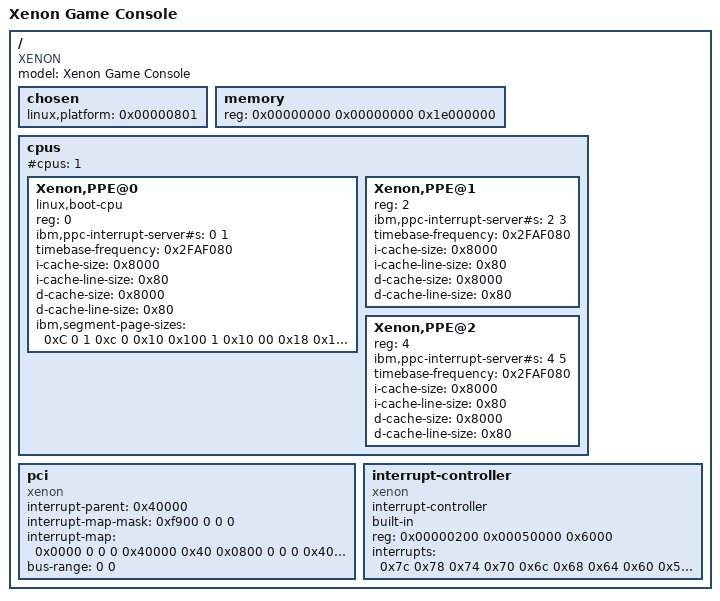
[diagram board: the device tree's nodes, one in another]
/*
 * xenon.dts - Xbox360 Game Console device tree.
 *
 *  This program is free software; you can redistribute it and/or modify
 *  it under the terms of the GNU General Public License as published by
 *  the Free Software Foundation; version 2 of the License.
 *
 *  This program is distributed in the hope that it will be useful,
 *  but WITHOUT ANY WARRANTY; without even the implied warranty of
 *  MERCHANTABILITY or FITNESS FOR A PARTICULAR PURPOSE.  See the
 *  GNU General Public License for more details.
 *
 *  You should have received a copy of the GNU General Public License
 *  along with this program; if not, write to the Free Software
 *  Foundation, Inc., 59 Temple Place, Suite 330, Boston, MA  02111-1307  USA
 */

/dts-v1/;

/ {
	model = "Xenon Game Console";
	compatible = "XENON";
	#address-cells = <2>;
	#size-cells = <1>;

	/*
     * Bootargs will be created here, as well as initrd properties if relevant
     */
	chosen {
		linux,platform = <0x00000801>;
	};

	memory {
		device_type = "memory";
		reg = <0x00000000 0x00000000 0x1e000000>;
	};

	cpus {
		#cpus = <1>;
		#address-cells = <1>;
		#size-cells = <0>;

		Xenon,PPE@0 {
			device_type = "cpu";
			linux,boot-cpu;
			reg = <0>;
			ibm,ppc-interrupt-server#s = <0 1>;
			timebase-frequency = <0x2FAF080>; // 50 MHz
			i-cache-size = <0x8000>;
			i-cache-line-size = <0x80>;
			d-cache-size = <0x8000>;
			d-cache-line-size = <0x80>;

					/* this must be configured with regard to the HID6:LB value */
			ibm,segment-page-sizes = <
				0xC   0     1 0xc   0     // 4k page
				0x10  0x100 1 0x10 00     // 64k pages
				0x18  0x110 1 0x18 01     // 16M pages
			>;
		};
		Xenon,PPE@1 {
			device_type = "cpu";
			reg = <2>;
			ibm,ppc-interrupt-server#s = <2 3>;
			timebase-frequency = <0x2FAF080>;
			i-cache-size = <0x8000>;
			i-cache-line-size = <0x80>;
			d-cache-size = <0x8000>;
			d-cache-line-size = <0x80>;
		};
		Xenon,PPE@2 {
			device_type = "cpu";
			reg = <4>;
			ibm,ppc-interrupt-server#s = <4 5>;
			timebase-frequency = <0x2FAF080>;
			i-cache-size = <0x8000>;
			i-cache-line-size = <0x80>;
			d-cache-size = <0x8000>;
			d-cache-line-size = <0x80>;
		};
	};

	pci {
		compatible = "xenon";
		device_type = "pci";
		#address-cells = <3>;  // phy up, mid, low
		#size-cells = <1>;
		#interrupt-cells = <1>;
		
		interrupt-parent = <0x40000>;
		// interrupts = <18 2>;
		interrupt-map-mask = <0xf900 0 0 0>; // type, lower, upper, irq

		interrupt-map = <
			0x0000 0 0 0  0x40000 0x40  // XMA
			0x0800 0 0 0  0x40000 0x24  // SATA cdrom
			0x1000 0 0 0  0x40000 0x20  // SATA disk
			0x2000 0 0 0  0x40000 0x2c  // USB OHCI #1
			0x2100 0 0 0  0x40000 0x30  // USB EHCI #1
			0x2800 0 0 0  0x40000 0x34  // USB OHCI #2
			0x2900 0 0 0  0x40000 0x38  // USB EHCI #2
			0x3800 0 0 0  0x40000 0x4c  // Enet
			0x4000 0 0 0  0x40000 0x18  // Flash
			0x4800 0 0 0  0x40000 0x44  // audio out
			0x5000 0 0 0  0x40000 0x14  // SMM, GPIO, ...
			0x7800 0 0 0  0x40000 0x58  // Xenos
		>;

		bus-range = <0 0>;
		ranges = <
			0x02000000 0x00000000 0x80000000 0x00000200 0x80000000 0x80000000 // PCI space at 80000000 is mapped to 200 80000000
			0x02000000 0x00000000 0x00000000 0x00000000 0x00000000 0x20000000 // RAM is 1:1 mapped
		>;
	};

	interrupt-controller {
		compatible = "xenon";
		linux,phandle = <0x40000>;
		interrupt-controller;
		#address-cells = <0>;
		#interrupt-cells = <1>;
		built-in;
		reg = <0x00000200 0x00050000 0x6000>;
		interrupts = <
			0x7c 0x78 0x74 0x70 0x6c 0x68 0x64 0x60
			0x5c 0x58 0x54 0x50 0x4c 0x48 0x44 0x40
			0x3c 0x38 0x34 0x30 0x2c 0x28 0x24 0x20
			0x1c 0x18 0x14 0x10 0x0c 0x08 0x04
		>;
	};
};
